VERSION ""

NS_ :

BS_:

BU_: BCM DriverInfoModule_DIM
VAL_TABLE_ VtEngineStatus 1 "On" 0 "OFF" ;
VAL_TABLE_ VtPowerMode 9 "Crank" 7 "Run" 6 "IgnitionOn" 3 "KeyApproved" 2 "Acc" 1 "Keyin" 0 "Kayout" ;
VAL_TABLE_ CarMode 2 "Transport" 1 "Factory" 0 "Normal" ;

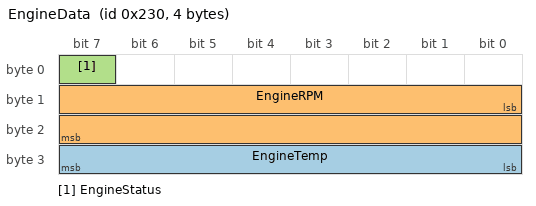
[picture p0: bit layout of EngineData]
BO_ 560 EngineData: 4 DriverInfoModule_DIM
 SG_ EngineTemp : 24|8@1- (2,50) [-25|45] "DegC"  DriverInfoModule_DIM
 SG_ EngineRPM : 8|16@1+ (0.0227272727272727,0) [0|1489.43181818182] "RPM"  DriverInfoModule_DIM
 SG_ EngineStatus : 7|1@1+ (1,0) [0|1] ""  DriverInfoModule_DIM

BO_ 128 PowerMode: 2 DriverInfoModule_DIM
 SG_ PowerMode : 8|4@1+ (1,0) [0|15] ""  BCM
 SG_ CarMode : 0|3@1+ (1,0) [0|7] ""  BCM

BA_DEF_ BO_  "GenMsgSendType" ENUM  "Cyclic","Event","EventPeriodic";
BA_DEF_ BO_  "GenMsgCycleTime" INT 0 0;
BA_DEF_DEF_  "GenMsgSendType" "Cyclic";
BA_DEF_DEF_  "GenMsgCycleTime" 0;
BA_ "GenMsgCycleTime" BO_ 560 100;
BA_ "GenMsgSendType" BO_ 128 2;
BA_ "GenMsgCycleTime" BO_ 128 10;
VAL_ 560 EngineStatus 1 "On" 0 "OFF" ;
VAL_ 128 PowerMode 9 "Crank" 7 "Run" 6 "IgnitionOn" 3 "KeyApproved" 2 "Acc" 1 "Keyin" 0 "Kayout" ;
VAL_ 128 CarMode 2 "Transport" 1 "Factory" 0 "Normal" ;
